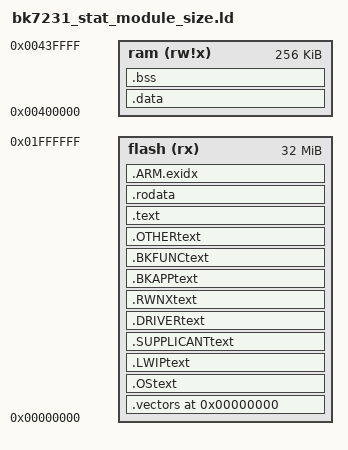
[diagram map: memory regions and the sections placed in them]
/* 
 * Script for GNU linker.
 * Describes layout of sections, location of stack.
 *
 * In this case vectors are at location 0 (reset @ 0x08)
 *
 * +------------+  0x00400000
 * data         |
 * end
 * |(heap)      |
 * .            .
 * .            .
 * |(heap limit)|
 *
 * |- - - - - - |
 * stack bottom    256k
 * +------------+  
 *
 * +------------+  0x0000000
 * |vectors     |
 * |            |
 * |------------+
 * |text        |  
 * |data        |
 * |            |  1024k
 * +------------+
 */


/* Split memory into area for vectors and ram */
MEMORY
{
	flash  (rx) : ORIGIN = 0x00000000, LENGTH = 32M
	ram   (rw!x): ORIGIN = 0x00400000, LENGTH = 256k
}

OUTPUT_FORMAT("elf32-littlearm", "elf32-littlearm", "elf32-littlearm")
OUTPUT_ARCH(arm)
ENTRY(_vector_start);
_vector_start = 0x00000000;

SECTIONS
{
/* vectors go to vectors region */
	. = 0x00000000;
	.vectors : 
	{ 
      KEEP(*(*.vectors))
	} > flash
	
	
	. = ALIGN(0x8);
	.OStext : 
	{
		os\mem_arch.o(.text)
		os\str_arch.o(.text)
		os\str_arch.o(.text.*)
		os\FreeRTOSv9.0.0\rtos_pub.o(.text)
		os\FreeRTOSv9.0.0\rtos_pub.o(.text.*)
		FreeRTOSv9.0.0\FreeRTOS\Source\croutine.o(.text)
		FreeRTOSv9.0.0\FreeRTOS\Source\croutine.o(.text.*)
		FreeRTOSv9.0.0\FreeRTOS\Source\event_groups.o(.text)
		FreeRTOSv9.0.0\FreeRTOS\Source\event_groups.o(.text.*)
		FreeRTOSv9.0.0\FreeRTOS\Source\list.o(.text)
		FreeRTOSv9.0.0\FreeRTOS\Source\list.o(.text.*)
		FreeRTOSv9.0.0\FreeRTOS\Source\queue.o(.text)
		FreeRTOSv9.0.0\FreeRTOS\Source\queue.o(.text.*)
		FreeRTOSv9.0.0\FreeRTOS\Source\tasks.o(.text)
		FreeRTOSv9.0.0\FreeRTOS\Source\tasks.o(.text.*)
		FreeRTOSv9.0.0\FreeRTOS\Source\timers.o(.text)
		FreeRTOSv9.0.0\FreeRTOS\Source\timers.o(.text.*)
		FreeRTOSv9.0.0\FreeRTOS\Source\portable\Keil\ARM968es\port.o(.text)
		FreeRTOSv9.0.0\FreeRTOS\Source\portable\Keil\ARM968es\port.o(.text.*)
		FreeRTOSv9.0.0\FreeRTOS\Source\portable\MemMang\heap_4.o(.text)
		FreeRTOSv9.0.0\FreeRTOS\Source\portable\MemMang\heap_4.o(.text.*)
	} > flash

	. = ALIGN(0x8);
	.LWIPtext : 
	{
		func\lwip_intf\lwip-2.0.2\port\ethernetif.o(.text)
		func\lwip_intf\lwip-2.0.2\port\net.o(.text)
		func\lwip_intf\lwip-2.0.2\port\sys_arch.o(.text)
		func\lwip_intf\lwip-2.0.2\src\api\api_lib.o(.text)
		func\lwip_intf\lwip-2.0.2\src\api\api_msg.o(.text)
		func\lwip_intf\lwip-2.0.2\src\api\err.o(.text)
		func\lwip_intf\lwip-2.0.2\src\api\netbuf.o(.text)
		func\lwip_intf\lwip-2.0.2\src\api\netdb.o(.text)
		func\lwip_intf\lwip-2.0.2\src\api\netifapi.o(.text)
		func\lwip_intf\lwip-2.0.2\src\api\sockets.o(.text)
		func\lwip_intf\lwip-2.0.2\src\api\tcpip.o(.text)
		func\lwip_intf\lwip-2.0.2\src\core\def.o(.text)
		func\lwip_intf\lwip-2.0.2\src\core\dns.o(.text)
		func\lwip_intf\lwip-2.0.2\src\core\inet_chksum.o(.text)
		func\lwip_intf\lwip-2.0.2\src\core\init.o(.text)
		func\lwip_intf\lwip-2.0.2\src\core\ip.o(.text)
		func\lwip_intf\lwip-2.0.2\src\core\mem.o(.text)
		func\lwip_intf\lwip-2.0.2\src\core\memp.o(.text)
		func\lwip_intf\lwip-2.0.2\src\core\netif.o(.text)
		func\lwip_intf\lwip-2.0.2\src\core\pbuf.o(.text)
		func\lwip_intf\lwip-2.0.2\src\core\raw.o(.text)
		func\lwip_intf\lwip-2.0.2\src\core\stats.o(.text)
		func\lwip_intf\lwip-2.0.2\src\core\sys.o(.text)
		func\lwip_intf\lwip-2.0.2\src\core\tcp.o(.text)
		func\lwip_intf\lwip-2.0.2\src\core\tcp_in.o(.text)
		func\lwip_intf\lwip-2.0.2\src\core\tcp_out.o(.text)
		func\lwip_intf\lwip-2.0.2\src\core\timeouts.o(.text)
		func\lwip_intf\lwip-2.0.2\src\core\udp.o(.text)
		func\lwip_intf\lwip-2.0.2\src\core\ipv4\autoip.o(.text)
		func\lwip_intf\lwip-2.0.2\src\core\ipv4\dhcp.o(.text)
		func\lwip_intf\lwip-2.0.2\src\core\ipv4\etharp.o(.text)
		func\lwip_intf\lwip-2.0.2\src\core\ipv4\icmp.o(.text)
		func\lwip_intf\lwip-2.0.2\src\core\ipv4\igmp.o(.text)
		func\lwip_intf\lwip-2.0.2\src\core\ipv4\ip4.o(.text)
		func\lwip_intf\lwip-2.0.2\src\core\ipv4\ip4_addr.o(.text)
		func\lwip_intf\lwip-2.0.2\src\core\ipv4\ip4_frag.o(.text)
		func\lwip_intf\lwip-2.0.2\src\core\ipv6\dhcp6.o(.text)
		func\lwip_intf\lwip-2.0.2\src\core\ipv6\ethip6.o(.text)
		func\lwip_intf\lwip-2.0.2\src\core\ipv6\icmp6.o(.text)
		func\lwip_intf\lwip-2.0.2\src\core\ipv6\inet6.o(.text)
		func\lwip_intf\lwip-2.0.2\src\core\ipv6\ip6.o(.text)
		func\lwip_intf\lwip-2.0.2\src\core\ipv6\ip6_addr.o(.text)
		func\lwip_intf\lwip-2.0.2\src\core\ipv6\ip6_frag.o(.text)
		func\lwip_intf\lwip-2.0.2\src\core\ipv6\mld6.o(.text)
		func\lwip_intf\lwip-2.0.2\src\core\ipv6\nd6.o(.text)
		func\lwip_intf\lwip-2.0.2\src\netif\ethernet.o(.text)
		func\lwip_intf\lwip-2.0.2\src\netif\lowpan6.o(.text)
		func\lwip_intf\lwip-2.0.2\src\netif\ppp\auth.o(.text)
		func\lwip_intf\lwip-2.0.2\src\netif\ppp\ccp.o(.text)
		func\lwip_intf\lwip-2.0.2\src\netif\ppp\chap-md5.o(.text)
		func\lwip_intf\lwip-2.0.2\src\netif\ppp\chap-new.o(.text)
		func\lwip_intf\lwip-2.0.2\src\netif\ppp\chap_ms.o(.text)
		func\lwip_intf\lwip-2.0.2\src\netif\ppp\demand.o(.text)
		func\lwip_intf\lwip-2.0.2\src\netif\ppp\eap.o(.text)
		func\lwip_intf\lwip-2.0.2\src\netif\ppp\ecp.o(.text)
		func\lwip_intf\lwip-2.0.2\src\netif\ppp\eui64.o(.text)
		func\lwip_intf\lwip-2.0.2\src\netif\ppp\fsm.o(.text)
		func\lwip_intf\lwip-2.0.2\src\netif\ppp\ipcp.o(.text)
		func\lwip_intf\lwip-2.0.2\src\netif\ppp\ipv6cp.o(.text)
		func\lwip_intf\lwip-2.0.2\src\netif\ppp\lcp.o(.text)
		func\lwip_intf\lwip-2.0.2\src\netif\ppp\magic.o(.text)
		func\lwip_intf\lwip-2.0.2\src\netif\ppp\mppe.o(.text)
		func\lwip_intf\lwip-2.0.2\src\netif\ppp\multilink.o(.text)
		func\lwip_intf\lwip-2.0.2\src\netif\ppp\ppp.o(.text)
		func\lwip_intf\lwip-2.0.2\src\netif\ppp\pppapi.o(.text)
		func\lwip_intf\lwip-2.0.2\src\netif\ppp\pppcrypt.o(.text)
		func\lwip_intf\lwip-2.0.2\src\netif\ppp\pppoe.o(.text)
		func\lwip_intf\lwip-2.0.2\src\netif\ppp\pppol2tp.o(.text)
		func\lwip_intf\lwip-2.0.2\src\netif\ppp\pppos.o(.text)
		func\lwip_intf\lwip-2.0.2\src\netif\ppp\upap.o(.text)
		func\lwip_intf\lwip-2.0.2\src\netif\ppp\utils.o(.text)
		func\lwip_intf\lwip-2.0.2\src\netif\ppp\vj.o(.text)
		func\lwip_intf\lwip-2.0.2\src\netif\ppp\polarssl\arc4.o(.text)
		func\lwip_intf\lwip-2.0.2\src\netif\ppp\polarssl\des.o(.text)
		func\lwip_intf\lwip-2.0.2\src\netif\ppp\polarssl\md4.o(.text)
		func\lwip_intf\lwip-2.0.2\src\netif\ppp\polarssl\md5.o(.text)
		func\lwip_intf\lwip-2.0.2\src\netif\ppp\polarssl\sha1.o(.text)
		func\lwip_intf\lwip-2.0.2\port\ethernetif.o(.text.*)
		func\lwip_intf\lwip-2.0.2\port\net.o(.text.*)
		func\lwip_intf\lwip-2.0.2\port\sys_arch.o(.text.*)
		func\lwip_intf\lwip-2.0.2\src\api\api_lib.o(.text.*)
		func\lwip_intf\lwip-2.0.2\src\api\api_msg.o(.text.*)
		func\lwip_intf\lwip-2.0.2\src\api\err.o(.text.*)
		func\lwip_intf\lwip-2.0.2\src\api\netbuf.o(.text.*)
		func\lwip_intf\lwip-2.0.2\src\api\netdb.o(.text.*)
		func\lwip_intf\lwip-2.0.2\src\api\netifapi.o(.text.*)
		func\lwip_intf\lwip-2.0.2\src\api\sockets.o(.text.*)
		func\lwip_intf\lwip-2.0.2\src\api\tcpip.o(.text.*)
		func\lwip_intf\lwip-2.0.2\src\core\def.o(.text.*)
		func\lwip_intf\lwip-2.0.2\src\core\dns.o(.text.*)
		func\lwip_intf\lwip-2.0.2\src\core\inet_chksum.o(.text.*)
		func\lwip_intf\lwip-2.0.2\src\core\init.o(.text.*)
		func\lwip_intf\lwip-2.0.2\src\core\ip.o(.text.*)
		func\lwip_intf\lwip-2.0.2\src\core\mem.o(.text.*)
		func\lwip_intf\lwip-2.0.2\src\core\memp.o(.text.*)
		func\lwip_intf\lwip-2.0.2\src\core\netif.o(.text.*)
		func\lwip_intf\lwip-2.0.2\src\core\pbuf.o(.text.*)
		func\lwip_intf\lwip-2.0.2\src\core\raw.o(.text.*)
		func\lwip_intf\lwip-2.0.2\src\core\stats.o(.text.*)
		func\lwip_intf\lwip-2.0.2\src\core\sys.o(.text.*)
		func\lwip_intf\lwip-2.0.2\src\core\tcp.o(.text.*)
		func\lwip_intf\lwip-2.0.2\src\core\tcp_in.o(.text.*)
		func\lwip_intf\lwip-2.0.2\src\core\tcp_out.o(.text.*)
		func\lwip_intf\lwip-2.0.2\src\core\timeouts.o(.text.*)
		func\lwip_intf\lwip-2.0.2\src\core\udp.o(.text.*)
		func\lwip_intf\lwip-2.0.2\src\core\ipv4\autoip.o(.text.*)
		func\lwip_intf\lwip-2.0.2\src\core\ipv4\dhcp.o(.text.*)
		func\lwip_intf\lwip-2.0.2\src\core\ipv4\etharp.o(.text.*)
		func\lwip_intf\lwip-2.0.2\src\core\ipv4\icmp.o(.text.*)
		func\lwip_intf\lwip-2.0.2\src\core\ipv4\igmp.o(.text.*)
		func\lwip_intf\lwip-2.0.2\src\core\ipv4\ip4.o(.text.*)
		func\lwip_intf\lwip-2.0.2\src\core\ipv4\ip4_addr.o(.text.*)
		func\lwip_intf\lwip-2.0.2\src\core\ipv4\ip4_frag.o(.text.*)
		func\lwip_intf\lwip-2.0.2\src\core\ipv6\dhcp6.o(.text.*)
		func\lwip_intf\lwip-2.0.2\src\core\ipv6\ethip6.o(.text.*)
		func\lwip_intf\lwip-2.0.2\src\core\ipv6\icmp6.o(.text.*)
		func\lwip_intf\lwip-2.0.2\src\core\ipv6\inet6.o(.text.*)
		func\lwip_intf\lwip-2.0.2\src\core\ipv6\ip6.o(.text.*)
		func\lwip_intf\lwip-2.0.2\src\core\ipv6\ip6_addr.o(.text.*)
		func\lwip_intf\lwip-2.0.2\src\core\ipv6\ip6_frag.o(.text.*)
		func\lwip_intf\lwip-2.0.2\src\core\ipv6\mld6.o(.text.*)
		func\lwip_intf\lwip-2.0.2\src\core\ipv6\nd6.o(.text.*)
		func\lwip_intf\lwip-2.0.2\src\netif\ethernet.o(.text.*)
		func\lwip_intf\lwip-2.0.2\src\netif\lowpan6.o(.text.*)
		func\lwip_intf\lwip-2.0.2\src\netif\ppp\auth.o(.text.*)
		func\lwip_intf\lwip-2.0.2\src\netif\ppp\ccp.o(.text.*)
		func\lwip_intf\lwip-2.0.2\src\netif\ppp\chap-md5.o(.text.*)
		func\lwip_intf\lwip-2.0.2\src\netif\ppp\chap-new.o(.text.*)
		func\lwip_intf\lwip-2.0.2\src\netif\ppp\chap_ms.o(.text.*)
		func\lwip_intf\lwip-2.0.2\src\netif\ppp\demand.o(.text.*)
		func\lwip_intf\lwip-2.0.2\src\netif\ppp\eap.o(.text.*)
		func\lwip_intf\lwip-2.0.2\src\netif\ppp\ecp.o(.text.*)
		func\lwip_intf\lwip-2.0.2\src\netif\ppp\eui64.o(.text.*)
		func\lwip_intf\lwip-2.0.2\src\netif\ppp\fsm.o(.text.*)
		func\lwip_intf\lwip-2.0.2\src\netif\ppp\ipcp.o(.text.*)
		func\lwip_intf\lwip-2.0.2\src\netif\ppp\ipv6cp.o(.text.*)
		func\lwip_intf\lwip-2.0.2\src\netif\ppp\lcp.o(.text.*)
		func\lwip_intf\lwip-2.0.2\src\netif\ppp\magic.o(.text.*)
		func\lwip_intf\lwip-2.0.2\src\netif\ppp\mppe.o(.text.*)
		func\lwip_intf\lwip-2.0.2\src\netif\ppp\multilink.o(.text.*)
		func\lwip_intf\lwip-2.0.2\src\netif\ppp\ppp.o(.text.*)
		func\lwip_intf\lwip-2.0.2\src\netif\ppp\pppapi.o(.text.*)
		func\lwip_intf\lwip-2.0.2\src\netif\ppp\pppcrypt.o(.text.*)
		func\lwip_intf\lwip-2.0.2\src\netif\ppp\pppoe.o(.text.*)
		func\lwip_intf\lwip-2.0.2\src\netif\ppp\pppol2tp.o(.text.*)
		func\lwip_intf\lwip-2.0.2\src\netif\ppp\pppos.o(.text.*)
		func\lwip_intf\lwip-2.0.2\src\netif\ppp\upap.o(.text.*)
		func\lwip_intf\lwip-2.0.2\src\netif\ppp\utils.o(.text.*)
		func\lwip_intf\lwip-2.0.2\src\netif\ppp\vj.o(.text.*)
		func\lwip_intf\lwip-2.0.2\src\netif\ppp\polarssl\arc4.o(.text.*)
		func\lwip_intf\lwip-2.0.2\src\netif\ppp\polarssl\des.o(.text.*)
		func\lwip_intf\lwip-2.0.2\src\netif\ppp\polarssl\md4.o(.text.*)
		func\lwip_intf\lwip-2.0.2\src\netif\ppp\polarssl\md5.o(.text.*)
		func\lwip_intf\lwip-2.0.2\src\netif\ppp\polarssl\sha1.o(.text.*)
	} > flash
	
	. = ALIGN(0x8);
	.SUPPLICANTtext : 
	{		
		func\hostapd-2.5\bk_patch\ddrv.o(.text)
		func\hostapd-2.5\bk_patch\fake_socket.o(.text)
		func\hostapd-2.5\bk_patch\signal.o(.text)
		func\hostapd-2.5\bk_patch\sk_intf.o(.text)
		func\hostapd-2.5\hostapd\main_none.o(.text)
		func\hostapd-2.5\src\ap\ap_config.o(.text)
		func\hostapd-2.5\src\ap\ap_drv_ops.o(.text)
		func\hostapd-2.5\src\ap\ap_list.o(.text)
		func\hostapd-2.5\src\ap\ap_mlme.o(.text)
		func\hostapd-2.5\src\ap\authsrv.o(.text)
		func\hostapd-2.5\src\ap\beacon.o(.text)
		func\hostapd-2.5\src\ap\bss_load.o(.text)
		func\hostapd-2.5\src\ap\dfs.o(.text)
		func\hostapd-2.5\src\ap\drv_callbacks.o(.text)
		func\hostapd-2.5\src\ap\eap_user_db.o(.text)
		func\hostapd-2.5\src\ap\hostapd.o(.text)
		func\hostapd-2.5\src\ap\hw_features.o(.text)
		func\hostapd-2.5\src\ap\ieee802_11.o(.text)
		func\hostapd-2.5\src\ap\ieee802_11_auth.o(.text)
		func\hostapd-2.5\src\ap\ieee802_11_ht.o(.text)
		func\hostapd-2.5\src\ap\ieee802_11_shared.o(.text)
		func\hostapd-2.5\src\ap\ieee802_1x.o(.text)
		func\hostapd-2.5\src\ap\pmksa_cache_auth.o(.text)
		func\hostapd-2.5\src\ap\sta_info.o(.text)
		func\hostapd-2.5\src\ap\tkip_countermeasures.o(.text)
		func\hostapd-2.5\src\ap\utils.o(.text)
		func\hostapd-2.5\src\ap\wmm.o(.text)
		func\hostapd-2.5\src\ap\wpa_auth.o(.text)
		func\hostapd-2.5\src\ap\wpa_auth_glue.o(.text)
		func\hostapd-2.5\src\ap\wpa_auth_ie.o(.text)
		func\hostapd-2.5\src\common\hw_features_common.o(.text)
		func\hostapd-2.5\src\common\ieee802_11_common.o(.text)
		func\hostapd-2.5\src\common\wpa_common.o(.text)
		func\hostapd-2.5\src\crypto\aes-internal-dec.o(.text)
		func\hostapd-2.5\src\crypto\aes-internal-enc.o(.text)
		func\hostapd-2.5\src\crypto\aes-internal.o(.text)
		func\hostapd-2.5\src\crypto\aes-unwrap.o(.text)
		func\hostapd-2.5\src\crypto\aes-wrap.o(.text)
		func\hostapd-2.5\src\crypto\md5-internal.o(.text)
		func\hostapd-2.5\src\crypto\md5.o(.text)
		func\hostapd-2.5\src\crypto\rc4.o(.text)
		func\hostapd-2.5\src\crypto\sha1-internal.o(.text)
		func\hostapd-2.5\src\crypto\sha1-pbkdf2.o(.text)
		func\hostapd-2.5\src\crypto\sha1-prf.o(.text)
		func\hostapd-2.5\src\crypto\sha1.o(.text)
		func\hostapd-2.5\src\crypto\tls_none.o(.text)
		func\hostapd-2.5\src\drivers\drivers.o(.text)
		func\hostapd-2.5\src\drivers\driver_beken.o(.text)
		func\hostapd-2.5\src\drivers\driver_common.o(.text)
		func\hostapd-2.5\src\eapol_auth\eapol_auth_sm.o(.text)
		func\hostapd-2.5\src\eap_common\eap_common.o(.text)
		func\hostapd-2.5\src\eap_server\eap_server.o(.text)
		func\hostapd-2.5\src\eap_server\eap_server_methods.o(.text)
		func\hostapd-2.5\src\l2_packet\l2_packet_none.o(.text)
		func\hostapd-2.5\src\rsn_supp\preauth.o(.text)
		func\hostapd-2.5\src\rsn_supp\wpa.o(.text)
		func\hostapd-2.5\src\rsn_supp\wpa_ie.o(.text)
		func\hostapd-2.5\src\utils\common.o(.text)
		func\hostapd-2.5\src\utils\eloop.o(.text)
		func\hostapd-2.5\src\utils\os_none.o(.text)
		func\hostapd-2.5\src\utils\wpabuf.o(.text)
		func\hostapd-2.5\wpa_supplicant\ap.o(.text)
		func\hostapd-2.5\wpa_supplicant\blacklist.o(.text)
		func\hostapd-2.5\wpa_supplicant\bss.o(.text)
		func\hostapd-2.5\wpa_supplicant\config.o(.text)
		func\hostapd-2.5\wpa_supplicant\config_none.o(.text)
		func\hostapd-2.5\wpa_supplicant\eap_register.o(.text)
		func\hostapd-2.5\wpa_supplicant\events.o(.text)
		func\hostapd-2.5\wpa_supplicant\main_supplicant.o(.text)
		func\hostapd-2.5\wpa_supplicant\notify.o(.text)
		func\hostapd-2.5\wpa_supplicant\wmm_ac.o(.text)
		func\hostapd-2.5\wpa_supplicant\wpas_glue.o(.text)
		func\hostapd-2.5\wpa_supplicant\wpa_scan.o(.text)
		func\hostapd-2.5\wpa_supplicant\wpa_supplicant.o(.text)		
		func\hostapd-2.5\bk_patch\ddrv.o(.text.*)
		func\hostapd-2.5\bk_patch\fake_socket.o(.text.*)
		func\hostapd-2.5\bk_patch\signal.o(.text.*)
		func\hostapd-2.5\bk_patch\sk_intf.o(.text.*)
		func\hostapd-2.5\hostapd\main_none.o(.text.*)
		func\hostapd-2.5\src\ap\ap_config.o(.text.*)
		func\hostapd-2.5\src\ap\ap_drv_ops.o(.text.*)
		func\hostapd-2.5\src\ap\ap_list.o(.text.*)
		func\hostapd-2.5\src\ap\ap_mlme.o(.text.*)
		func\hostapd-2.5\src\ap\authsrv.o(.text.*)
		func\hostapd-2.5\src\ap\beacon.o(.text.*)
		func\hostapd-2.5\src\ap\bss_load.o(.text.*)
		func\hostapd-2.5\src\ap\dfs.o(.text.*)
		func\hostapd-2.5\src\ap\drv_callbacks.o(.text.*)
		func\hostapd-2.5\src\ap\eap_user_db.o(.text.*)
		func\hostapd-2.5\src\ap\hostapd.o(.text.*)
		func\hostapd-2.5\src\ap\hw_features.o(.text.*)
		func\hostapd-2.5\src\ap\ieee802_11.o(.text.*)
		func\hostapd-2.5\src\ap\ieee802_11_auth.o(.text.*)
		func\hostapd-2.5\src\ap\ieee802_11_ht.o(.text.*)
		func\hostapd-2.5\src\ap\ieee802_11_shared.o(.text.*)
		func\hostapd-2.5\src\ap\ieee802_1x.o(.text.*)
		func\hostapd-2.5\src\ap\pmksa_cache_auth.o(.text.*)
		func\hostapd-2.5\src\ap\sta_info.o(.text.*)
		func\hostapd-2.5\src\ap\tkip_countermeasures.o(.text.*)
		func\hostapd-2.5\src\ap\utils.o(.text.*)
		func\hostapd-2.5\src\ap\wmm.o(.text.*)
		func\hostapd-2.5\src\ap\wpa_auth.o(.text.*)
		func\hostapd-2.5\src\ap\wpa_auth_glue.o(.text.*)
		func\hostapd-2.5\src\ap\wpa_auth_ie.o(.text.*)
		func\hostapd-2.5\src\common\hw_features_common.o(.text.*)
		func\hostapd-2.5\src\common\ieee802_11_common.o(.text.*)
		func\hostapd-2.5\src\common\wpa_common.o(.text.*)
		func\hostapd-2.5\src\crypto\aes-internal-dec.o(.text.*)
		func\hostapd-2.5\src\crypto\aes-internal-enc.o(.text.*)
		func\hostapd-2.5\src\crypto\aes-internal.o(.text.*)
		func\hostapd-2.5\src\crypto\aes-unwrap.o(.text.*)
		func\hostapd-2.5\src\crypto\aes-wrap.o(.text.*)
		func\hostapd-2.5\src\crypto\md5-internal.o(.text.*)
		func\hostapd-2.5\src\crypto\md5.o(.text.*)
		func\hostapd-2.5\src\crypto\rc4.o(.text.*)
		func\hostapd-2.5\src\crypto\sha1-internal.o(.text.*)
		func\hostapd-2.5\src\crypto\sha1-pbkdf2.o(.text.*)
		func\hostapd-2.5\src\crypto\sha1-prf.o(.text.*)
		func\hostapd-2.5\src\crypto\sha1.o(.text.*)
		func\hostapd-2.5\src\crypto\tls_none.o(.text.*)
		func\hostapd-2.5\src\drivers\drivers.o(.text.*)
		func\hostapd-2.5\src\drivers\driver_beken.o(.text.*)
		func\hostapd-2.5\src\drivers\driver_common.o(.text.*)
		func\hostapd-2.5\src\eapol_auth\eapol_auth_sm.o(.text.*)
		func\hostapd-2.5\src\eap_common\eap_common.o(.text.*)
		func\hostapd-2.5\src\eap_server\eap_server.o(.text.*)
		func\hostapd-2.5\src\eap_server\eap_server_methods.o(.text.*)
		func\hostapd-2.5\src\l2_packet\l2_packet_none.o(.text.*)
		func\hostapd-2.5\src\rsn_supp\preauth.o(.text.*)
		func\hostapd-2.5\src\rsn_supp\wpa.o(.text.*)
		func\hostapd-2.5\src\rsn_supp\wpa_ie.o(.text.*)
		func\hostapd-2.5\src\utils\common.o(.text.*)
		func\hostapd-2.5\src\utils\eloop.o(.text.*)
		func\hostapd-2.5\src\utils\os_none.o(.text.*)
		func\hostapd-2.5\src\utils\wpabuf.o(.text.*)
		func\hostapd-2.5\wpa_supplicant\ap.o(.text.*)
		func\hostapd-2.5\wpa_supplicant\blacklist.o(.text.*)
		func\hostapd-2.5\wpa_supplicant\bss.o(.text.*)
		func\hostapd-2.5\wpa_supplicant\config.o(.text.*)
		func\hostapd-2.5\wpa_supplicant\config_none.o(.text.*)
		func\hostapd-2.5\wpa_supplicant\eap_register.o(.text.*)
		func\hostapd-2.5\wpa_supplicant\events.o(.text.*)
		func\hostapd-2.5\wpa_supplicant\main_supplicant.o(.text.*)
		func\hostapd-2.5\wpa_supplicant\notify.o(.text.*)
		func\hostapd-2.5\wpa_supplicant\wmm_ac.o(.text.*)
		func\hostapd-2.5\wpa_supplicant\wpas_glue.o(.text.*)
		func\hostapd-2.5\wpa_supplicant\wpa_scan.o(.text.*)
		func\hostapd-2.5\wpa_supplicant\wpa_supplicant.o(.text.*)
	} > flash
	
	. = ALIGN(0x8);
	.DRIVERtext : 
	{		
		driver\driver.o(.text)
		driver\audio\audio.o(.text)
		driver\audio\audio_adc.o(.text)
		driver\audio\audio_dac.o(.text)
		driver\audio\ring_buffer.o(.text)
		driver\audio\ring_buffer_dma_read.o(.text)
		driver\audio\ring_buffer_dma_write.o(.text)
		driver\codec\driver_codec_es8374.o(.text)
		driver\common\dd.o(.text)
		driver\common\drv_model.o(.text)
		driver\dma\dma.o(.text)
		driver\entry\arch_main.o(.text)
		driver\fft\fft.o(.text)
		driver\flash\flash.o(.text)
		driver\general_dma\general_dma.o(.text)
		driver\gpio\gpio.o(.text)
		driver\i2c\i2c1.o(.text)
		driver\i2c\i2c2.o(.text)
		driver\i2s\i2s.o(.text)
		driver\icu\icu.o(.text)
		driver\intc\intc.o(.text)
		driver\irda\irda.o(.text)
		driver\jpeg\jpeg_encoder.o(.text)
		driver\macphy_bypass\mac_phy_bypass.o(.text)
		driver\phy\phy_trident.o(.text)
		driver\pwm\bk_timer.o(.text)
		driver\pwm\mcu_ps_timer.o(.text)
		driver\pwm\pwm.o(.text)
		driver\rw_pub\rw_platf_pub.o(.text)
		driver\saradc\saradc.o(.text)
		driver\sdcard\sdcard.o(.text)
		driver\sdcard\sdio_driver.o(.text)
		driver\sdio\sdio.o(.text)
		driver\sdio\sdma.o(.text)
		driver\sdio\sutil.o(.text)
		driver\spi\spi.o(.text)
		driver\spidma\spidma.o(.text)
		driver\sys_ctrl\sys_ctrl.o(.text)
		driver\uart\Retarget.o(.text)
		driver\uart\uart.o(.text)
		driver\wdt\wdt.o(.text)		
		driver\driver.o(.text.*)
		driver\audio\audio.o(.text.*)
		driver\audio\audio_adc.o(.text.*)
		driver\audio\audio_dac.o(.text.*)
		driver\audio\ring_buffer.o(.text.*)
		driver\audio\ring_buffer_dma_read.o(.text.*)
		driver\audio\ring_buffer_dma_write.o(.text.*)
		driver\codec\driver_codec_es8374.o(.text.*)
		driver\common\dd.o(.text.*)
		driver\common\drv_model.o(.text.*)
		driver\dma\dma.o(.text.*)
		driver\entry\arch_main.o(.text.*)
		driver\fft\fft.o(.text.*)
		driver\flash\flash.o(.text.*)
		driver\general_dma\general_dma.o(.text.*)
		driver\gpio\gpio.o(.text.*)
		driver\i2c\i2c1.o(.text.*)
		driver\i2c\i2c2.o(.text.*)
		driver\i2s\i2s.o(.text.*)
		driver\icu\icu.o(.text.*)
		driver\intc\intc.o(.text.*)
		driver\irda\irda.o(.text.*)
		driver\jpeg\jpeg_encoder.o(.text.*)
		driver\macphy_bypass\mac_phy_bypass.o(.text.*)
		driver\phy\phy_trident.o(.text.*)
		driver\pwm\bk_timer.o(.text.*)
		driver\pwm\mcu_ps_timer.o(.text.*)
		driver\pwm\pwm.o(.text.*)
		driver\rw_pub\rw_platf_pub.o(.text.*)
		driver\saradc\saradc.o(.text.*)
		driver\sdcard\sdcard.o(.text.*)
		driver\sdcard\sdio_driver.o(.text.*)
		driver\sdio\sdio.o(.text.*)
		driver\sdio\sdma.o(.text.*)
		driver\sdio\sutil.o(.text.*)
		driver\spi\spi.o(.text.*)
		driver\spidma\spidma.o(.text.*)
		driver\sys_ctrl\sys_ctrl.o(.text.*)
		driver\uart\Retarget.o(.text.*)
		driver\uart\uart.o(.text.*)
		driver\wdt\wdt.o(.text.*)
	} > flash
	
	. = ALIGN(0x8);
	.RWNXtext : 
	{		
		ip\common\co_dlist.o(.text)
		ip\common\co_list.o(.text)
		ip\common\co_math.o(.text)
		ip\common\co_pool.o(.text)
		ip\common\co_ring.o(.text)
		ip\ke\ke_env.o(.text)
		ip\ke\ke_event.o(.text)
		ip\ke\ke_msg.o(.text)
		ip\ke\ke_queue.o(.text)
		ip\ke\ke_task.o(.text)
		ip\ke\ke_timer.o(.text)
		ip\lmac\src\chan\chan.o(.text)
		ip\lmac\src\hal\hal_desc.o(.text)
		ip\lmac\src\hal\hal_dma.o(.text)
		ip\lmac\src\hal\hal_machw.o(.text)
		ip\lmac\src\hal\hal_mib.o(.text)
		ip\lmac\src\mm\mm.o(.text)
		ip\lmac\src\mm\mm_bcn.o(.text)
		ip\lmac\src\mm\mm_task.o(.text)
		ip\lmac\src\mm\mm_timer.o(.text)
		ip\lmac\src\p2p\p2p.o(.text)
		ip\lmac\src\ps\ps.o(.text)
		ip\lmac\src\rd\rd.o(.text)
		ip\lmac\src\rwnx\rwnx.o(.text)
		ip\lmac\src\rx\rx_swdesc.o(.text)
		ip\lmac\src\rx\rxl\rxl_cntrl.o(.text)
		ip\lmac\src\rx\rxl\rxl_hwdesc.o(.text)
		ip\lmac\src\scan\scan.o(.text)
		ip\lmac\src\scan\scan_shared.o(.text)
		ip\lmac\src\scan\scan_task.o(.text)
		ip\lmac\src\sta\sta_mgmt.o(.text)
		ip\lmac\src\td\td.o(.text)
		ip\lmac\src\tdls\tdls.o(.text)
		ip\lmac\src\tdls\tdls_task.o(.text)
		ip\lmac\src\tpc\tpc.o(.text)
		ip\lmac\src\tx\tx_swdesc.o(.text)
		ip\lmac\src\tx\txl\txl_buffer.o(.text)
		ip\lmac\src\tx\txl\txl_buffer_shared.o(.text)
		ip\lmac\src\tx\txl\txl_cfm.o(.text)
		ip\lmac\src\tx\txl\txl_cntrl.o(.text)
		ip\lmac\src\tx\txl\txl_frame.o(.text)
		ip\lmac\src\tx\txl\txl_frame_shared.o(.text)
		ip\lmac\src\tx\txl\txl_hwdesc.o(.text)
		ip\lmac\src\vif\vif_mgmt.o(.text)
		ip\mac\mac.o(.text)
		ip\mac\mac_ie.o(.text)
		ip\umac\src\apm\apm.o(.text)
		ip\umac\src\apm\apm_task.o(.text)
		ip\umac\src\bam\bam.o(.text)
		ip\umac\src\bam\bam_task.o(.text)
		ip\umac\src\me\me.o(.text)
		ip\umac\src\me\me_mgmtframe.o(.text)
		ip\umac\src\me\me_mic.o(.text)
		ip\umac\src\me\me_task.o(.text)
		ip\umac\src\me\me_utils.o(.text)
		ip\umac\src\rc\rc.o(.text)
		ip\umac\src\rc\rc_basic.o(.text)
		ip\umac\src\rxu\rxu_cntrl.o(.text)
		ip\umac\src\scanu\scanu.o(.text)
		ip\umac\src\scanu\scanu_shared.o(.text)
		ip\umac\src\scanu\scanu_task.o(.text)
		ip\umac\src\sm\sm.o(.text)
		ip\umac\src\sm\sm_task.o(.text)
		ip\umac\src\txu\txu_cntrl.o(.text)		
		ip\common\co_dlist.o(.text.*)
		ip\common\co_list.o(.text.*)
		ip\common\co_math.o(.text.*)
		ip\common\co_pool.o(.text.*)
		ip\common\co_ring.o(.text.*)
		ip\ke\ke_env.o(.text.*)
		ip\ke\ke_event.o(.text.*)
		ip\ke\ke_msg.o(.text.*)
		ip\ke\ke_queue.o(.text.*)
		ip\ke\ke_task.o(.text.*)
		ip\ke\ke_timer.o(.text.*)
		ip\lmac\src\chan\chan.o(.text.*)
		ip\lmac\src\hal\hal_desc.o(.text.*)
		ip\lmac\src\hal\hal_dma.o(.text.*)
		ip\lmac\src\hal\hal_machw.o(.text.*)
		ip\lmac\src\hal\hal_mib.o(.text.*)
		ip\lmac\src\mm\mm.o(.text.*)
		ip\lmac\src\mm\mm_bcn.o(.text.*)
		ip\lmac\src\mm\mm_task.o(.text.*)
		ip\lmac\src\mm\mm_timer.o(.text.*)
		ip\lmac\src\p2p\p2p.o(.text.*)
		ip\lmac\src\ps\ps.o(.text.*)
		ip\lmac\src\rd\rd.o(.text.*)
		ip\lmac\src\rwnx\rwnx.o(.text.*)
		ip\lmac\src\rx\rx_swdesc.o(.text.*)
		ip\lmac\src\rx\rxl\rxl_cntrl.o(.text.*)
		ip\lmac\src\rx\rxl\rxl_hwdesc.o(.text.*)
		ip\lmac\src\scan\scan.o(.text.*)
		ip\lmac\src\scan\scan_shared.o(.text.*)
		ip\lmac\src\scan\scan_task.o(.text.*)
		ip\lmac\src\sta\sta_mgmt.o(.text.*)
		ip\lmac\src\td\td.o(.text.*)
		ip\lmac\src\tdls\tdls.o(.text.*)
		ip\lmac\src\tdls\tdls_task.o(.text.*)
		ip\lmac\src\tpc\tpc.o(.text.*)
		ip\lmac\src\tx\tx_swdesc.o(.text.*)
		ip\lmac\src\tx\txl\txl_buffer.o(.text.*)
		ip\lmac\src\tx\txl\txl_buffer_shared.o(.text.*)
		ip\lmac\src\tx\txl\txl_cfm.o(.text.*)
		ip\lmac\src\tx\txl\txl_cntrl.o(.text.*)
		ip\lmac\src\tx\txl\txl_frame.o(.text.*)
		ip\lmac\src\tx\txl\txl_frame_shared.o(.text.*)
		ip\lmac\src\tx\txl\txl_hwdesc.o(.text.*)
		ip\lmac\src\vif\vif_mgmt.o(.text.*)
		ip\mac\mac.o(.text.*)
		ip\mac\mac_ie.o(.text.*)
		ip\umac\src\apm\apm.o(.text.*)
		ip\umac\src\apm\apm_task.o(.text.*)
		ip\umac\src\bam\bam.o(.text.*)
		ip\umac\src\bam\bam_task.o(.text.*)
		ip\umac\src\me\me.o(.text.*)
		ip\umac\src\me\me_mgmtframe.o(.text.*)
		ip\umac\src\me\me_mic.o(.text.*)
		ip\umac\src\me\me_task.o(.text.*)
		ip\umac\src\me\me_utils.o(.text.*)
		ip\umac\src\rc\rc.o(.text.*)
		ip\umac\src\rc\rc_basic.o(.text.*)
		ip\umac\src\rxu\rxu_cntrl.o(.text.*)
		ip\umac\src\scanu\scanu.o(.text.*)
		ip\umac\src\scanu\scanu_shared.o(.text.*)
		ip\umac\src\scanu\scanu_task.o(.text.*)
		ip\umac\src\sm\sm.o(.text.*)
		ip\umac\src\sm\sm_task.o(.text.*)
		ip\umac\src\txu\txu_cntrl.o(.text.*)
	} > flash
	
	. = ALIGN(0x8);
	.BKAPPtext : 
	{		
		app\app.o(.text)
		app\ate_app.o(.text)
		app\airkiss\airkiss_main.o(.text)
		app\config\param_config.o(.text)
		app\ftp\ftpd.o(.text)
		app\ftp\vfs.o(.text)
		app\http\lite-log.o(.text)
		app\http\utils_httpc.o(.text)
		app\http\utils_net.o(.text)
		app\http\utils_timer.o(.text)
		app\led\app_led.o(.text)
		app\net_work\app_drone.o(.text)
		app\net_work\app_lwip_tcp.o(.text)
		app\net_work\app_lwip_udp.o(.text)
		app\standalone-ap\sa_ap.o(.text)
		app\standalone-station\sa_station.o(.text)
		app\tftp\tftpclient.o(.text)
		app\app.o(.text.*)
		app\ate_app.o(.text.*)
		app\airkiss\airkiss_main.o(.text.*)
		app\config\param_config.o(.text.*)
		app\ftp\ftpd.o(.text.*)
		app\ftp\vfs.o(.text.*)
		app\http\lite-log.o(.text.*)
		app\http\utils_httpc.o(.text.*)
		app\http\utils_net.o(.text.*)
		app\http\utils_timer.o(.text.*)
		app\led\app_led.o(.text.*)
		app\net_work\app_drone.o(.text.*)
		app\net_work\app_lwip_tcp.o(.text.*)
		app\net_work\app_lwip_udp.o(.text.*)
		app\standalone-ap\sa_ap.o(.text.*)
		app\standalone-station\sa_station.o(.text.*)
		app\tftp\tftpclient.o(.text.*)
	} > flash
	
	. = ALIGN(0x8);
	.BKFUNCtext : 
	{		
		func\func.o(.text)
		func\audio\audio_intf.o(.text)
		func\bk7011_cal\bk7011_cal.o(.text)
		func\bk7011_cal\bk7221U_cal.o(.text)
		func\bk7011_cal\bk7231U_cal.o(.text)
		func\bk7011_cal\bk7231_cal.o(.text)
		func\bk7011_cal\manual_cal_bk7231.o(.text)
		func\bk7011_cal\manual_cal_bk7231U.o(.text)
		func\camera_intf\camera_inft.o(.text)
		func\hostapd_intf\hostapd_intf.o(.text)
		func\joint_up\reconnect_startup.o(.text)
		func\joint_up\role_launch.o(.text)
		func\key\key_main.o(.text)
		func\key\multi_button.o(.text)
		func\key_handle\key_handle.o(.text)
		func\lwip_intf\platform_stub.o(.text)
		func\lwip_intf\tcp_server.o(.text)
		func\lwip_intf\dhcpd\dhcp-server-main.o(.text)
		func\lwip_intf\dhcpd\dhcp-server.o(.text)
		func\misc\fake_clock.o(.text)
		func\misc\pseudo_random.o(.text)
		func\misc\target_util.o(.text)
		func\music_player\app_music.o(.text)
		func\music_player\driver_audio_if.o(.text)
		func\music_player\fs_fat\disk_io.o(.text)
		func\music_player\fs_fat\ff.o(.text)
		func\music_player\fs_fat\ffsystem.o(.text)
		func\music_player\fs_fat\ffunicode.o(.text)
		func\music_player\fs_fat\playmode.o(.text)
		func\music_player\Mp3Lib\bitstream.o(.text)
		func\music_player\Mp3Lib\buffers.o(.text)
		func\music_player\Mp3Lib\dct32.o(.text)
		func\music_player\Mp3Lib\dequant.o(.text)
		func\music_player\Mp3Lib\dqchan.o(.text)
		func\music_player\Mp3Lib\huffman.o(.text)
		func\music_player\Mp3Lib\hufftabs.o(.text)
		func\music_player\Mp3Lib\imdct.o(.text)
		func\music_player\Mp3Lib\layer21.o(.text)
		func\music_player\Mp3Lib\mp3dec.o(.text)
		func\music_player\Mp3Lib\mp3tabs.o(.text)
		func\music_player\Mp3Lib\mp3_play.o(.text)
		func\music_player\Mp3Lib\scalfact.o(.text)
		func\music_player\Mp3Lib\stproc.o(.text)
		func\music_player\Mp3Lib\subband.o(.text)
		func\music_player\Mp3Lib\trigtabs.o(.text)
		func\net_param_intf\net_param.o(.text)
		func\power_save\manual_ps.o(.text)
		func\power_save\mcu_ps.o(.text)
		func\power_save\power_save.o(.text)
		func\rf_test\rx_sensitivity.o(.text)
		func\rf_test\tx_evm.o(.text)
		func\rwnx_intf\rw_ieee80211.o(.text)
		func\rwnx_intf\rw_msdu.o(.text)
		func\rwnx_intf\rw_msg_rx.o(.text)
		func\rwnx_intf\rw_msg_tx.o(.text)
		func\sdio_intf\sdio_intf.o(.text)
		func\sdio_trans\sdio_trans.o(.text)
		func\sd_music\sdcard_test.o(.text)
		func\sim_uart\gpio_uart.o(.text)
		func\sim_uart\pwm_uart.o(.text)
		func\spidma_intf\spidma_intf.o(.text)
		func\temp_detect\temp_detect.o(.text)
		func\uart_debug\cmd_evm.o(.text)
		func\uart_debug\cmd_help.o(.text)
		func\uart_debug\cmd_reg.o(.text)
		func\uart_debug\cmd_rx_sensitivity.o(.text)
		func\uart_debug\command_line.o(.text)
		func\uart_debug\command_table.o(.text)
		func\uart_debug\udebug.o(.text)
		func\udisk_mp3\ump3.o(.text)
		func\usb\fusb.o(.text)
		func\user_driver\BkDriverFlash.o(.text)
		func\user_driver\BkDriverGpio.o(.text)
		func\user_driver\BkDriverPwm.o(.text)
		func\user_driver\BkDriverUart.o(.text)
		func\user_driver\BkDriverWdg.o(.text)
		func\video_transfer\video_transfer.o(.text)
		func\wlan_ui\extral_cli.o(.text)
		func\wlan_ui\wlan_cli.o(.text)
		func\wlan_ui\wlan_ui.o(.text)
		func\func.o(.text.*)
		func\audio\audio_intf.o(.text.*)
		func\bk7011_cal\bk7011_cal.o(.text.*)
		func\bk7011_cal\bk7221U_cal.o(.text.*)
		func\bk7011_cal\bk7231U_cal.o(.text.*)
		func\bk7011_cal\bk7231_cal.o(.text.*)
		func\bk7011_cal\manual_cal_bk7231.o(.text.*)
		func\bk7011_cal\manual_cal_bk7231U.o(.text.*)
		func\camera_intf\camera_inft.o(.text.*)
		func\hostapd_intf\hostapd_intf.o(.text.*)
		func\joint_up\reconnect_startup.o(.text.*)
		func\joint_up\role_launch.o(.text.*)
		func\key\key_main.o(.text.*)
		func\key\multi_button.o(.text.*)
		func\key_handle\key_handle.o(.text.*)
		func\lwip_intf\platform_stub.o(.text.*)
		func\lwip_intf\tcp_server.o(.text.*)
		func\lwip_intf\dhcpd\dhcp-server-main.o(.text.*)
		func\lwip_intf\dhcpd\dhcp-server.o(.text.*)
		func\misc\fake_clock.o(.text.*)
		func\misc\pseudo_random.o(.text.*)
		func\misc\target_util.o(.text.*)
		func\music_player\app_music.o(.text.*)
		func\music_player\driver_audio_if.o(.text.*)
		func\music_player\fs_fat\disk_io.o(.text.*)
		func\music_player\fs_fat\ff.o(.text.*)
		func\music_player\fs_fat\ffsystem.o(.text.*)
		func\music_player\fs_fat\ffunicode.o(.text.*)
		func\music_player\fs_fat\playmode.o(.text.*)
		func\music_player\Mp3Lib\bitstream.o(.text.*)
		func\music_player\Mp3Lib\buffers.o(.text.*)
		func\music_player\Mp3Lib\dct32.o(.text.*)
		func\music_player\Mp3Lib\dequant.o(.text.*)
		func\music_player\Mp3Lib\dqchan.o(.text.*)
		func\music_player\Mp3Lib\huffman.o(.text.*)
		func\music_player\Mp3Lib\hufftabs.o(.text.*)
		func\music_player\Mp3Lib\imdct.o(.text.*)
		func\music_player\Mp3Lib\layer21.o(.text.*)
		func\music_player\Mp3Lib\mp3dec.o(.text.*)
		func\music_player\Mp3Lib\mp3tabs.o(.text.*)
		func\music_player\Mp3Lib\mp3_play.o(.text.*)
		func\music_player\Mp3Lib\scalfact.o(.text.*)
		func\music_player\Mp3Lib\stproc.o(.text.*)
		func\music_player\Mp3Lib\subband.o(.text.*)
		func\music_player\Mp3Lib\trigtabs.o(.text.*)
		func\net_param_intf\net_param.o(.text.*)
		func\power_save\manual_ps.o(.text.*)
		func\power_save\mcu_ps.o(.text.*)
		func\power_save\power_save.o(.text.*)
		func\rf_test\rx_sensitivity.o(.text.*)
		func\rf_test\tx_evm.o(.text.*)
		func\rwnx_intf\rw_ieee80211.o(.text.*)
		func\rwnx_intf\rw_msdu.o(.text.*)
		func\rwnx_intf\rw_msg_rx.o(.text.*)
		func\rwnx_intf\rw_msg_tx.o(.text.*)
		func\sdio_intf\sdio_intf.o(.text.*)
		func\sdio_trans\sdio_trans.o(.text.*)
		func\sd_music\sdcard_test.o(.text.*)
		func\sim_uart\gpio_uart.o(.text.*)
		func\sim_uart\pwm_uart.o(.text.*)
		func\spidma_intf\spidma_intf.o(.text.*)
		func\temp_detect\temp_detect.o(.text.*)
		func\uart_debug\cmd_evm.o(.text.*)
		func\uart_debug\cmd_help.o(.text.*)
		func\uart_debug\cmd_reg.o(.text.*)
		func\uart_debug\cmd_rx_sensitivity.o(.text.*)
		func\uart_debug\command_line.o(.text.*)
		func\uart_debug\command_table.o(.text.*)
		func\uart_debug\udebug.o(.text.*)
		func\udisk_mp3\ump3.o(.text.*)
		func\usb\fusb.o(.text.*)
		func\user_driver\BkDriverFlash.o(.text.*)
		func\user_driver\BkDriverGpio.o(.text.*)
		func\user_driver\BkDriverPwm.o(.text.*)
		func\user_driver\BkDriverUart.o(.text.*)
		func\user_driver\BkDriverWdg.o(.text.*)
		func\video_transfer\video_transfer.o(.text.*)
		func\wlan_ui\extral_cli.o(.text.*)
		func\wlan_ui\wlan_cli.o(.text.*)
		func\wlan_ui\wlan_ui.o(.text.*)
	} > flash
	
	. = ALIGN(0x8);
	.OTHERtext : 
	{		
		demo\ieee802_11_demo.o(.text)
		demo\ieee802_11_demo.o(.text.*)
	} > flash	

	. = ALIGN(0x8);
	.text : 
	{
	    *(.text)
	    *(.text.*)
	    *(.stub)
	    /* .gnu.warning sections are handled specially by elf32.em.  */
	    *(.gnu.warning)
	    *(.gnu.linkonce.t*)
	    *(.glue_7t) *(.glue_7)
	} > flash	

/* read only data.for example: const int rom_data[3]={1,2,3}; */
	.rodata ALIGN(8) : 
	{
		*(.rodata)
		*(.rodata.*)
		*(.gnu.linkonce.r*)
	} > flash
	
	.ARM.exidx :
	{
	    *(.ARM.exidx*)
	    *(.gnu.linkonce.armexidx.*)
	} > flash
	
/* globals.for example: int ram_data[3]={4,5,6}; */		/* VMA in RAM, but keep LMA in flash */
	_begin_data = .;
	.data : AT ( _begin_data )
	{
		*(.data .data.*)
		*(.sdata) 
		*(.gnu.linkonce.d*)
    	SORT(CONSTRUCTORS)
	} >ram
	
	/* Loader will copy data from _flash_begin to _ram_begin..ram_end */
	_data_flash_begin = LOADADDR(.data);
	_data_ram_begin = ADDR(.data);
	_data_ram_end = .;

/* uninitialized data section - global   int i; */
	.bss ALIGN(8):
	{
		_bss_start = .;
		*boot_handlers.O(.bss .bss.* .scommon .sbss .dynbss COMMON)
		*(.bss .bss.*)
		*(.scommon)
		*(.sbss)
		*(.dynbss)
		*(COMMON)
		/* Align here to ensure that the .bss section occupies space up to
		_end.  Align after .bss to ensure correct alignment even if the
		.bss section disappears because there are no input sections.  */
		. = ALIGN(32 / 8);
		_bss_end = .;
	} > ram						/* in RAM */

	. = ALIGN (8);
	_empty_ram = .;

/* This symbol defines end of code/data sections. Heap starts here. */
	PROVIDE(end    	  = .);
	
/* _stack symbol defines initial stack bottom addres. Stack grows to lower addresses.
   Typically you set this to be top of your RAM. Note: code never checks, if stack
   grows into heap area!
*/
	PROVIDE(_stack_unused      = 0x440000 - 0x3F0 - 0x7F0 - 0xFF0 - 0x3F0 - 0x10); /* 0x10*/
	PROVIDE(_stack_svc         = 0x440000 - 0x3F0 - 0x7F0 - 0xFF0 - 0x3F0); /* 0x3F0*/
	PROVIDE(_stack_irq         = 0x440000 - 0x3F0 - 0x7F0 - 0xFF0); /* 0xFF0*/
	PROVIDE(_stack_fiq         = 0x440000 - 0x3F0 - 0x7F0); /* 0x7F0*/
	PROVIDE(_stack_sys         = 0x440000 - 0x3F0); /* 0x3F0*/
}
 GROUP(
   libgcc.a
   libg.a
   libc.a
   libm.a
   libnosys.a
 )
